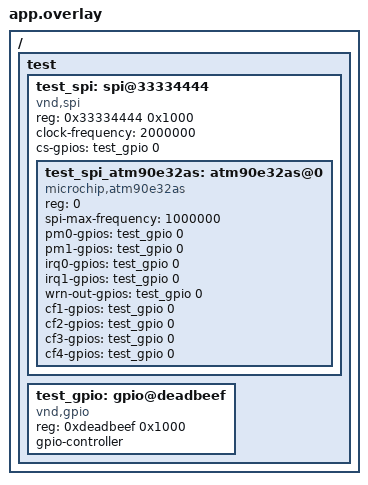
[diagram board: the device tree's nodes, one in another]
/*
 * Copyright (c) 2025 Pedro Ramos
 *
 * SPDX-License-Identifier: Apache-2.0
 */

/ {
	test {
		#address-cells = <1>;
		#size-cells = <1>;

		test_spi: spi@33334444 {
			compatible = "vnd,spi";
			reg = <0x33334444 0x1000>;
			#address-cells = <1>;
			#size-cells = <0>;
			clock-frequency = <2000000>;
			cs-gpios = <&test_gpio 0 0>;
			status = "okay";

			test_spi_atm90e32as: atm90e32as@0 {
				compatible = "microchip,atm90e32as";
				reg = <0>;
				spi-max-frequency = <1000000>;
				pm0-gpios = <&test_gpio 0 0>;
				pm1-gpios = <&test_gpio 0 0>;
				irq0-gpios = <&test_gpio 0 0>;
				irq1-gpios = <&test_gpio 0 0>;
				wrn-out-gpios = <&test_gpio 0 0>;
				cf1-gpios = <&test_gpio 0 0>;
				cf2-gpios = <&test_gpio 0 0>;
				cf3-gpios = <&test_gpio 0 0>;
				cf4-gpios = <&test_gpio 0 0>;
			};
		};

		test_gpio: gpio@deadbeef {
			compatible = "vnd,gpio";
			reg = <0xdeadbeef 0x1000>;
			gpio-controller;
			#gpio-cells = <0x2>;
			status = "okay";
		};
	};
};
